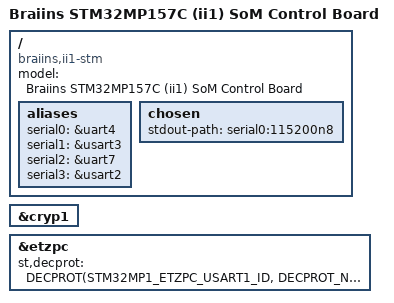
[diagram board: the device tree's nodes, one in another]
// SPDX-License-Identifier: (GPL-2.0+ OR BSD-3-Clause)
/*
 * Copyright (C) 2023  Braiins Systems s.r.o.
 *
 * This file is part of Braiins Open-Source Initiative (BOSI).
 *
 * BOSI is free software: you can redistribute it and/or modify
 * it under the terms of the GNU General Public License as published by
 * the Free Software Foundation, either version 3 of the License, or
 * (at your option) any later version.
 *
 * This program is distributed in the hope that it will be useful,
 * but WITHOUT ANY WARRANTY; without even the implied warranty of
 * MERCHANTABILITY or FITNESS FOR A PARTICULAR PURPOSE.  See the
 * GNU General Public License for more details.
 *
 * You should have received a copy of the GNU General Public License
 * along with this program.  If not, see <https://www.gnu.org/licenses/>.
 *
 * Please, keep in mind that we may also license BOSI or any part thereof
 * under a proprietary license. For more information on the terms and conditions
 * of such proprietary license or if you have any other questions, please
 * contact us at opensource@braiins.com.
 */

/dts-v1/;

#include "stm32mp157.dtsi"
#include "stm32mp15xc.dtsi"
#include "stm32mp15-pinctrl.dtsi"
#include "stm32mp15xxac-pinctrl.dtsi"
#include "stm32mp15xx-ya157c.dtsi"
#include <dt-bindings/soc/st,stm32-etzpc.h>

/ {
	model = "Braiins STM32MP157C (ii1) SoM Control Board";
	compatible = "braiins,ii1-stm", "st,stm32mp157";

	aliases {
		serial0 = &uart4;
		serial1 = &usart3;
		serial2 = &uart7;
		serial3 = &usart2;
	};

	chosen {
		stdout-path = "serial0:115200n8";
	};
};

&cryp1 {
	status = "okay";
};

&etzpc {
	st,decprot = <
		DECPROT(STM32MP1_ETZPC_USART1_ID, DECPROT_NS_RW, DECPROT_UNLOCK)
		DECPROT(STM32MP1_ETZPC_SPI6_ID, DECPROT_NS_RW, DECPROT_UNLOCK)
		DECPROT(STM32MP1_ETZPC_I2C4_ID, DECPROT_NS_RW, DECPROT_UNLOCK)
		DECPROT(STM32MP1_ETZPC_I2C6_ID, DECPROT_NS_RW, DECPROT_UNLOCK)
		DECPROT(STM32MP1_ETZPC_RNG1_ID, DECPROT_NS_RW, DECPROT_UNLOCK)
		DECPROT(STM32MP1_ETZPC_HASH1_ID, DECPROT_NS_RW, DECPROT_UNLOCK)
		DECPROT(STM32MP1_ETZPC_CRYP1_ID, DECPROT_NS_RW, DECPROT_UNLOCK)
		DECPROT(STM32MP1_ETZPC_DDRCTRL_ID, DECPROT_NS_R_S_W, DECPROT_LOCK)
		DECPROT(STM32MP1_ETZPC_DDRPHYC_ID, DECPROT_NS_R_S_W, DECPROT_LOCK)
		DECPROT(STM32MP1_ETZPC_STGENC_ID, DECPROT_S_RW, DECPROT_LOCK)
		DECPROT(STM32MP1_ETZPC_BKPSRAM_ID, DECPROT_S_RW, DECPROT_LOCK)
		DECPROT(STM32MP1_ETZPC_IWDG1_ID, DECPROT_S_RW, DECPROT_LOCK)
	>;
};
